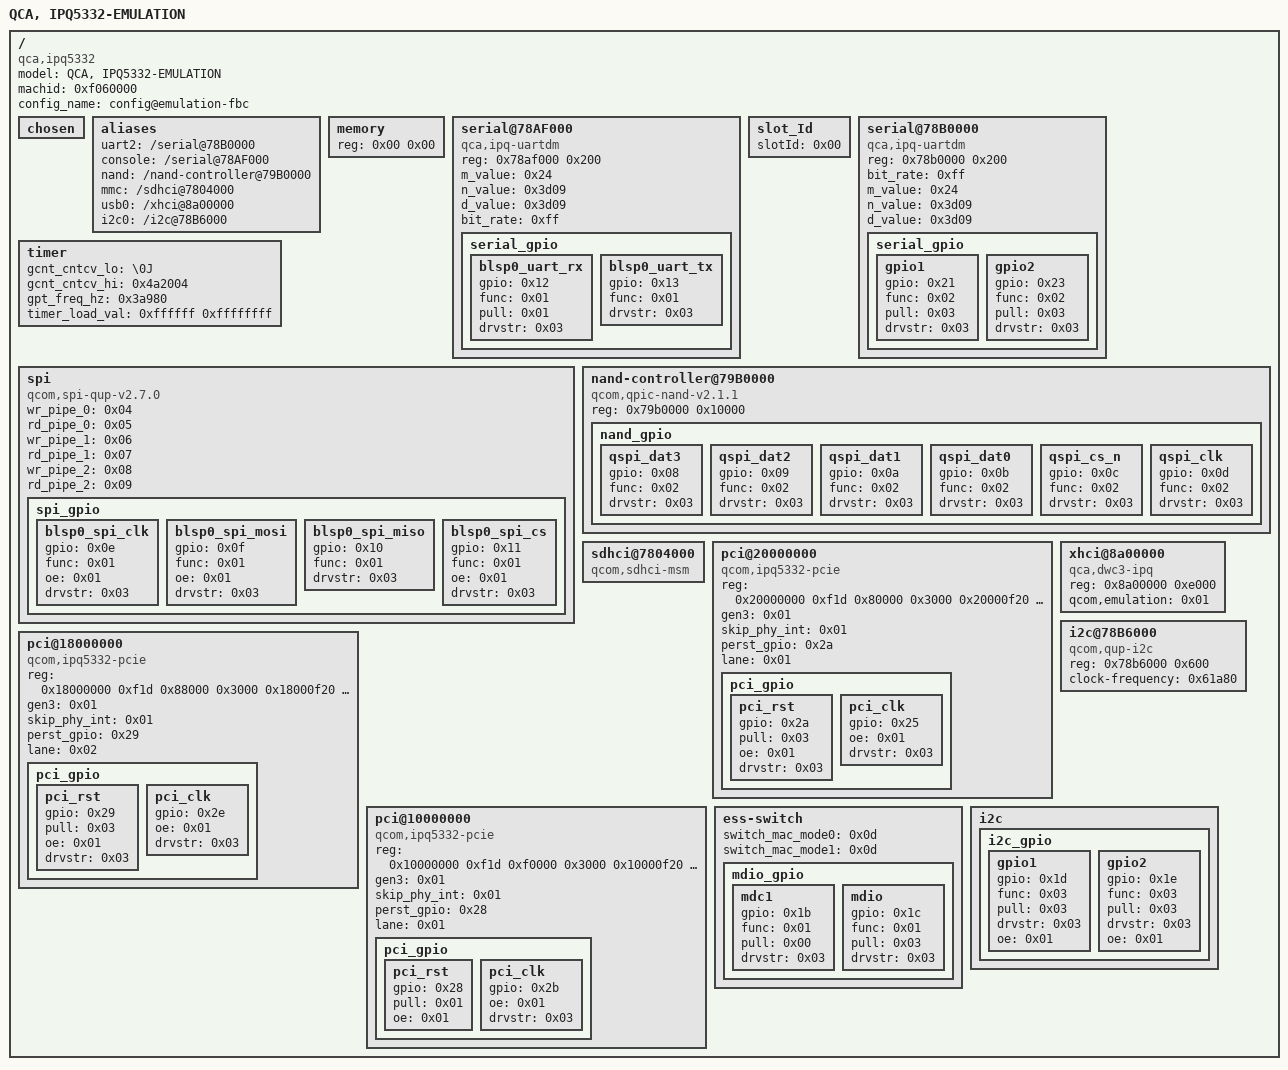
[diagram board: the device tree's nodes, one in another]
/dts-v1/;

/ {
	#address-cells = <0x01>;
	#size-cells = <0x01>;
	model = "QCA, IPQ5332-EMULATION";
	compatible = "qca,ipq5332\0qca,ipq5332-emulation";
	machid = <0xf060000>;
	config_name = "config@emulation-fbc";

	chosen {
	};

	aliases {
		uart2 = "/serial@78B0000";
		console = "/serial@78AF000";
		nand = "/nand-controller@79B0000";
		mmc = "/sdhci@7804000";
		usb0 = "/xhci@8a00000";
		i2c0 = "/i2c@78B6000";
	};

	memory {
		device_type = "memory";
		reg = <0x00 0x00>;
	};

	serial@78AF000 {
		compatible = "qca,ipq-uartdm";
		reg = <0x78af000 0x200>;
		m_value = <0x24>;
		n_value = <0x3d09>;
		d_value = <0x3d09>;
		bit_rate = <0xff>;
		status = "ok";

		serial_gpio {

			blsp0_uart_rx {
				gpio = <0x12>;
				func = <0x01>;
				pull = <0x01>;
				drvstr = <0x03>;
			};

			blsp0_uart_tx {
				gpio = <0x13>;
				func = <0x01>;
				drvstr = <0x03>;
			};
		};
	};

	slot_Id {
		slotId = <0x00>;
	};

	serial@78B0000 {
		compatible = "qca,ipq-uartdm";
		reg = <0x78b0000 0x200>;
		bit_rate = <0xff>;
		m_value = <0x24>;
		n_value = <0x3d09>;
		d_value = <0x3d09>;
		status = "ok";

		serial_gpio {

			gpio1 {
				gpio = <0x21>;
				func = <0x02>;
				pull = <0x03>;
				drvstr = <0x03>;
			};

			gpio2 {
				gpio = <0x23>;
				func = <0x02>;
				pull = <0x03>;
				drvstr = <0x03>;
			};
		};
	};

	timer {
		gcnt_cntcv_lo = "\0J ";
		gcnt_cntcv_hi = <0x4a2004>;
		gpt_freq_hz = <0x3a980>;
		timer_load_val = <0xffffff 0xffffffff>;
	};

	spi {
		compatible = "qcom,spi-qup-v2.7.0";
		wr_pipe_0 = <0x04>;
		rd_pipe_0 = <0x05>;
		wr_pipe_1 = <0x06>;
		rd_pipe_1 = <0x07>;
		wr_pipe_2 = <0x08>;
		rd_pipe_2 = <0x09>;
		status = "ok";

		spi_gpio {

			blsp0_spi_clk {
				gpio = <0x0e>;
				func = <0x01>;
				oe = <0x01>;
				drvstr = <0x03>;
			};

			blsp0_spi_mosi {
				gpio = <0x0f>;
				func = <0x01>;
				oe = <0x01>;
				drvstr = <0x03>;
			};

			blsp0_spi_miso {
				gpio = <0x10>;
				func = <0x01>;
				drvstr = <0x03>;
			};

			blsp0_spi_cs {
				gpio = <0x11>;
				func = <0x01>;
				oe = <0x01>;
				drvstr = <0x03>;
			};
		};
	};

	nand-controller@79B0000 {
		#address-cells = <0x01>;
		#size-cells = <0x00>;
		compatible = "qcom,qpic-nand-v2.1.1";
		reg = <0x79b0000 0x10000>;
		status = "okay";

		nand_gpio {

			qspi_dat3 {
				gpio = <0x08>;
				func = <0x02>;
				drvstr = <0x03>;
			};

			qspi_dat2 {
				gpio = <0x09>;
				func = <0x02>;
				drvstr = <0x03>;
			};

			qspi_dat1 {
				gpio = <0x0a>;
				func = <0x02>;
				drvstr = <0x03>;
			};

			qspi_dat0 {
				gpio = <0x0b>;
				func = <0x02>;
				drvstr = <0x03>;
			};

			qspi_cs_n {
				gpio = <0x0c>;
				func = <0x02>;
				drvstr = <0x03>;
			};

			qspi_clk {
				gpio = <0x0d>;
				func = <0x02>;
				drvstr = <0x03>;
			};
		};
	};

	sdhci@7804000 {
		compatible = "qcom,sdhci-msm";
		status = "okay";
	};

	pci@20000000 {
		compatible = "qcom,ipq5332-pcie";
		#address-cells = <0x01>;
		#size-cells = <0x01>;
		reg = <0x20000000 0xf1d 0x80000 0x3000 0x20000f20 0xa8 0x20001000 0x1000 0x20300000 0xd00000 0x20100000 0x100000 0x1829000 0x60 0x4b0000 0x800>;
		reg-names = "pci_dbi\0parf\0elbi\0dm_iatu\0axi_bars\0axi_conf\0pci_rst\0pci_phy";
		gen3 = <0x01>;
		status = "ok";
		skip_phy_int = <0x01>;
		perst_gpio = <0x2a>;
		lane = <0x01>;

		pci_gpio {

			pci_rst {
				gpio = <0x2a>;
				pull = <0x03>;
				oe = <0x01>;
				drvstr = <0x03>;
			};

			pci_clk {
				gpio = <0x25>;
				oe = <0x01>;
				drvstr = <0x03>;
			};
		};
	};

	pci@18000000 {
		compatible = "qcom,ipq5332-pcie";
		#address-cells = <0x01>;
		#size-cells = <0x01>;
		reg = <0x18000000 0xf1d 0x88000 0x3000 0x18000f20 0xa8 0x18001000 0x1000 0x18300000 0xd00000 0x18100000 0x100000 0x1828000 0x60 0x4b1000 0x1000>;
		reg-names = "pci_dbi\0parf\0elbi\0dm_iatu\0axi_bars\0axi_conf\0pci_rst\0pci_phy";
		gen3 = <0x01>;
		status = "ok";
		skip_phy_int = <0x01>;
		perst_gpio = <0x29>;
		lane = <0x02>;

		pci_gpio {

			pci_rst {
				gpio = <0x29>;
				pull = <0x03>;
				oe = <0x01>;
				drvstr = <0x03>;
			};

			pci_clk {
				gpio = <0x2e>;
				oe = <0x01>;
				drvstr = <0x03>;
			};
		};
	};

	pci@10000000 {
		compatible = "qcom,ipq5332-pcie";
		#address-cells = <0x01>;
		#size-cells = <0x01>;
		reg = <0x10000000 0xf1d 0xf0000 0x3000 0x10000f20 0xa8 0x10001000 0x1000 0x10300000 0xd00000 0x10100000 0x100000 0x182a000 0x60 0x4b1800 0x800>;
		reg-names = "pci_dbi\0parf\0elbi\0dm_iatu\0axi_bars\0axi_conf\0pci_rst\0pci_phy";
		gen3 = <0x01>;
		status = "ok";
		skip_phy_int = <0x01>;
		perst_gpio = <0x28>;
		lane = <0x01>;

		pci_gpio {

			pci_rst {
				gpio = <0x28>;
				pull = <0x01>;
				oe = <0x01>;
			};

			pci_clk {
				gpio = <0x2b>;
				oe = <0x01>;
				drvstr = <0x03>;
			};
		};
	};

	xhci@8a00000 {
		compatible = "qca,dwc3-ipq";
		#address-cells = <0x01>;
		#size-cells = <0x01>;
		reg = <0x8a00000 0xe000>;
		qcom,emulation = <0x01>;
	};

	i2c@78B6000 {
		compatible = "qcom,qup-i2c";
		#address-cells = <0x01>;
		#size-cells = <0x00>;
		reg = <0x78b6000 0x600>;
		clock-frequency = <0x61a80>;
	};

	ess-switch {
		switch_mac_mode0 = <0x0d>;
		switch_mac_mode1 = <0x0d>;

		mdio_gpio {

			mdc1 {
				gpio = <0x1b>;
				func = <0x01>;
				pull = <0x00>;
				drvstr = <0x03>;
			};

			mdio {
				gpio = <0x1c>;
				func = <0x01>;
				pull = <0x03>;
				drvstr = <0x03>;
			};
		};
	};

	i2c {

		i2c_gpio {

			gpio1 {
				gpio = <0x1d>;
				func = <0x03>;
				pull = <0x03>;
				drvstr = <0x03>;
				oe = <0x01>;
			};

			gpio2 {
				gpio = <0x1e>;
				func = <0x03>;
				pull = <0x03>;
				drvstr = <0x03>;
				oe = <0x01>;
			};
		};
	};
};
